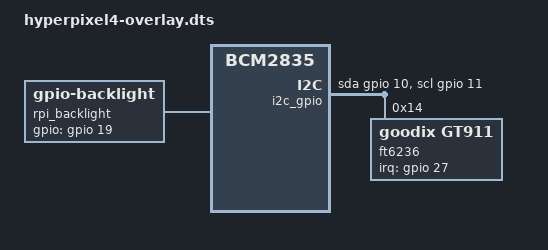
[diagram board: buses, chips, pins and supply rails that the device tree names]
/dts-v1/;
/plugin/;
/ {
    compatible = "brcm,bcm2835";

    fragment@0 {
        target = <&gpio>;
        __overlay__ {
            dpi18_pins: dpi18_pins {
                brcm,pins = <0 1 2 3 4 5 6 7 8 9 12 13 14 15 16 17 20 21 22 23 24 25>;
                brcm,function = <0x6>;
                brcm,pull = <0x0>;
            };
        };
    };
    fragment@1 {
        target-path = "/";
        __overlay__ {
            rpi_backlight: rpi_backlight {
                compatible = "gpio-backlight";
                gpios = <&gpio 19 0>;
                default-on;
                pinctrl-names = "default";
                pinctrl-0 = <&dpi18_pins>;
            };
        };
    };
    fragment@2 {
        target-path = "/";
        __overlay__ {
            i2c_gpio: i2c@0 {
                compatible = "i2c-gpio";
                gpios = <&gpio 10 0 /* sda */
                     &gpio 11 0 /* scl */
                    >;
                i2c-gpio,delay-us = <4>;        /* ~100 kHz */
                #address-cells = <1>;
                #size-cells = <0>;
            };
        };
    };
    fragment@3 {
        target = <&i2c_gpio>;
        __overlay__ {
            /* needed to avoid dtc warning */
            #address-cells = <1>;
            #size-cells = <0>;
            ft6236: ft6236@14 {
                compatible = "goodix,gt911";
                reg = <0x14>;
                interrupt-parent = <&gpio>;
                interrupts = <27 2>;
                touchscreen-size-x = <480>;
                touchscreen-size-y = <800>;
                touchscreen-x-mm = <51>;
                touchscreen-y-mm = <85>;
            };
        };
    };
    fragment@4 {
        target = <&ft6236>;
        __dormant__ {
            touchscreen-inverted-x;
        };
    };
    fragment@5 {
        target = <&ft6236>;
        __overlay__ {
            touchscreen-inverted-y;
        };
    };
    fragment@6 {
        target = <&ft6236>;
        __overlay__ {
            touchscreen-swapped-x-y;
        };
    };
    __overrides__ {
        touchscreen-inverted-x = <0>,"+4";
        touchscreen-inverted-y = <0>,"-5";
        touchscreen-swapped-x-y = <0>,"-6";
    };
};
